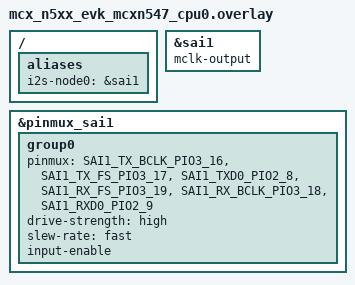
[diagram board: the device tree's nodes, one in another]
/*
 * Copyright 2026 NXP
 * SPDX-License-Identifier: Apache-2.0
 */

/* This board uses CONFIG_I2S_TEST_SEPARATE_DEVICES=n and connects TX and RX blocks in one
 * SAI peripheral by shorting signals externally on the EVK.  These are the HW changes
 * required to run this test:
 *	- Populate JP16 and JP20
 *	- Short BCLK JP20-pin3 (SAI1_RX_BCLK/P3_18) to JP20-pin1  (SAI1_TX_BCLK/P3_16)
 *	- SHort SYNC JP16-pin3 (SAI1_RX_FS  /P3_19) to JP16-pin1  (SAI1_TX_FS  /P3_17)
 *	- Short Data J20-pin14 (SAI1_RXD0   /P2_9)  to JP20-pin13 (SAI1_TXD0   /P2_8)
 */

/ {
	aliases {
		i2s-node0 = &sai1;
	};
};

&sai1 {
	mclk-output;
};

&pinmux_sai1 {
	group0 {
		pinmux = <SAI1_TX_BCLK_PIO3_16>,
			 <SAI1_TX_FS_PIO3_17>,
			 <SAI1_TXD0_PIO2_8>,
			 <SAI1_RX_FS_PIO3_19>,
			 <SAI1_RX_BCLK_PIO3_18>,
			 <SAI1_RXD0_PIO2_9>;
		drive-strength = "high";
		slew-rate = "fast";
		input-enable;
	};
};
